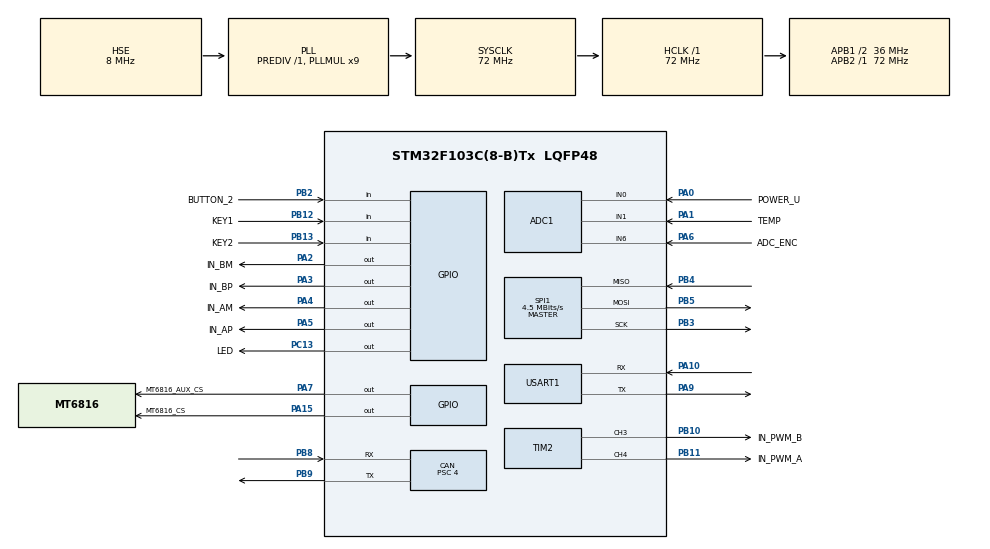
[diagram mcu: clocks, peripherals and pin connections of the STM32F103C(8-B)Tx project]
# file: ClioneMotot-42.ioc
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ADC1.Channel-0\#ChannelRegularConversion=ADC_CHANNEL_0
ADC1.Channel-1\#ChannelRegularConversion=ADC_CHANNEL_1
ADC1.Channel-2\#ChannelRegularConversion=ADC_CHANNEL_6
ADC1.Channel-3\#ChannelRegularConversion=ADC_CHANNEL_TEMPSENSOR
ADC1.NbrOfConversion=4
ADC1.NbrOfConversionFlag=1
ADC1.Rank-0\#ChannelRegularConversion=1
ADC1.Rank-1\#ChannelRegularConversion=2
ADC1.Rank-2\#ChannelRegularConversion=3
ADC1.Rank-3\#ChannelRegularConversion=4
ADC1.SamplingTime-0\#ChannelRegularConversion=ADC_SAMPLETIME_55CYCLES_5
ADC1.SamplingTime-1\#ChannelRegularConversion=ADC_SAMPLETIME_55CYCLES_5
ADC1.SamplingTime-2\#ChannelRegularConversion=ADC_SAMPLETIME_55CYCLES_5
ADC1.SamplingTime-3\#ChannelRegularConversion=ADC_SAMPLETIME_55CYCLES_5
ADC1.master=1
CAN.BS1=CAN_BS1_9TQ
CAN.BS2=CAN_BS2_8TQ
CAN.CalculateBaudRate=500000
CAN.CalculateTimeBit=2000
CAN.CalculateTimeQuantum=111.11111111111111
CAN.NART=ENABLE
CAN.Prescaler=4
Dma.ADC1.0.Direction=DMA_PERIPH_TO_MEMORY
Dma.ADC1.0.Instance=DMA1_Channel1
Dma.ADC1.0.MemDataAlignment=DMA_MDATAALIGN_HALFWORD
Dma.ADC1.0.MemInc=DMA_MINC_ENABLE
Dma.ADC1.0.Mode=DMA_CIRCULAR
Dma.ADC1.0.PeriphDataAlignment=DMA_PDATAALIGN_HALFWORD
Dma.ADC1.0.PeriphInc=DMA_PINC_DISABLE
Dma.ADC1.0.Priority=DMA_PRIORITY_HIGH
Dma.Request0=ADC1
Dma.Request1=USART1_RX
Dma.Request2=USART1_TX
Dma.USART1_RX.1.Direction=DMA_PERIPH_TO_MEMORY
Dma.USART1_RX.1.Instance=DMA1_Channel5
Dma.USART1_RX.1.MemDataAlignment=DMA_MDATAALIGN_BYTE
Dma.USART1_RX.1.MemInc=DMA_MINC_ENABLE
Dma.USART1_RX.1.Mode=DMA_NORMAL
Dma.USART1_RX.1.PeriphDataAlignment=DMA_PDATAALIGN_BYTE
Dma.USART1_RX.1.PeriphInc=DMA_PINC_DISABLE
Dma.USART1_RX.1.Priority=DMA_PRIORITY_HIGH
Dma.USART1_TX.2.Direction=DMA_MEMORY_TO_PERIPH
Dma.USART1_TX.2.Instance=DMA1_Channel4
Dma.USART1_TX.2.MemDataAlignment=DMA_MDATAALIGN_BYTE
Dma.USART1_TX.2.MemInc=DMA_MINC_ENABLE
Dma.USART1_TX.2.Mode=DMA_NORMAL
Dma.USART1_TX.2.PeriphDataAlignment=DMA_PDATAALIGN_BYTE
Dma.USART1_TX.2.PeriphInc=DMA_PINC_DISABLE
Dma.USART1_TX.2.Priority=DMA_PRIORITY_HIGH
FREERTOS.Tasks01=defaultTask,24,128,StartDefaultTask,Default,NULL,Dynamic,NULL,NULL
IWDG.Prescaler=IWDG_PRESCALER_64
Mcu.Family=STM32F1
Mcu.Name=STM32F103C(8-B)Tx
Mcu.Package=LQFP48
NVIC.CAN1_RX1_IRQn=true\:5\:0\:false\:false\:true\:true\:true\:true\:true
NVIC.CAN1_SCE_IRQn=true\:5\:0\:false\:false\:true\:true\:true\:true\:true
NVIC.DMA1_Channel1_IRQn=true\:5\:0\:false\:false\:true\:true\:false\:true\:true
NVIC.DMA1_Channel4_IRQn=true\:5\:0\:false\:false\:true\:true\:false\:true\:true
NVIC.DMA1_Channel5_IRQn=true\:5\:0\:false\:false\:true\:true\:false\:true\:true
NVIC.PriorityGroup=NVIC_PRIORITYGROUP_4
NVIC.TIM4_IRQn=true\:15\:0\:false\:false\:true\:false\:false\:true\:true
NVIC.TimeBase=TIM4_IRQn
NVIC.TimeBaseIP=TIM4
NVIC.USART1_IRQn=true\:5\:0\:false\:false\:true\:true\:true\:true\:true
NVIC.USB_HP_CAN1_TX_IRQn=true\:5\:0\:false\:false\:true\:true\:true\:true\:true
NVIC.USB_LP_CAN1_RX0_IRQn=true\:5\:0\:false\:false\:true\:true\:true\:true\:true
PA0-WKUP.GPIO_Label=POWER_U
PA0-WKUP.Signal=ADCx_IN0
PA1.GPIO_Label=TEMP
PA1.Signal=ADCx_IN1
PA10.Mode=Asynchronous
PA10.Signal=USART1_RX
PA13.Mode=Serial_Wire
PA13.Signal=SYS_JTMS-SWDIO
PA14.Mode=Serial_Wire
PA14.Signal=SYS_JTCK-SWCLK
PA15.GPIO_Label=MT6816_CS
PA15.GPIO_Speed=GPIO_SPEED_FREQ_HIGH
PA15.Signal=GPIO_Output
PA2.GPIO_Label=IN_BM
PA2.GPIO_Speed=GPIO_SPEED_FREQ_HIGH
PA2.PinState=GPIO_PIN_SET
PA2.Signal=GPIO_Output
PA3.GPIO_Label=IN_BP
PA3.GPIO_Speed=GPIO_SPEED_FREQ_HIGH
PA3.PinState=GPIO_PIN_SET
PA3.Signal=GPIO_Output
PA4.GPIO_Label=IN_AM
PA4.GPIO_Speed=GPIO_SPEED_FREQ_HIGH
PA4.PinState=GPIO_PIN_SET
PA4.Signal=GPIO_Output
PA5.GPIO_Label=IN_AP
PA5.GPIO_Speed=GPIO_SPEED_FREQ_HIGH
PA5.PinState=GPIO_PIN_SET
PA5.Signal=GPIO_Output
PA6.GPIO_Label=ADC_ENC
PA6.Signal=ADCx_IN6
PA7.GPIO_Label=MT6816_AUX_CS
PA7.GPIO_Speed=GPIO_SPEED_FREQ_HIGH
PA7.Signal=GPIO_Output
PA9.Mode=Asynchronous
PA9.Signal=USART1_TX
PB10.GPIO_Label=IN_PWM_B
PB10.Signal=S_TIM2_CH3
PB11.GPIO_Label=IN_PWM_A
PB11.Signal=S_TIM2_CH4
PB12.GPIO_Label=KEY1
PB12.GPIO_PuPd=GPIO_PULLUP
PB12.Signal=GPIO_Input
PB13.GPIO_Label=KEY2
PB13.Signal=GPIO_Input
PB2.GPIO_Label=BUTTON_2
PB2.GPIO_PuPd=GPIO_PULLUP
PB2.Signal=GPIO_Input
PB3.Mode=Full_Duplex_Master
PB3.Signal=SPI1_SCK
PB4.Mode=Full_Duplex_Master
PB4.Signal=SPI1_MISO
PB5.Mode=Full_Duplex_Master
PB5.Signal=SPI1_MOSI
PB8.Mode=CAN_Activate
PB8.Signal=CAN_RX
PB9.Mode=CAN_Activate
PB9.Signal=CAN_TX
PC13-TAMPER-RTC.GPIO_Label=LED
PC13-TAMPER-RTC.Signal=GPIO_Output
PD0-OSC_IN.Mode=HSE-External-Oscillator
PD0-OSC_IN.Signal=RCC_OSC_IN
PD1-OSC_OUT.Mode=HSE-External-Oscillator
PD1-OSC_OUT.Signal=RCC_OSC_OUT
ProjectManager.HeapSize=0x200
ProjectManager.StackSize=0x400
ProjectManager.TargetToolchain=CMake
RCC.ADCPresc=RCC_ADCPCLK2_DIV6
RCC.AHBFreq_Value=72000000
RCC.APB1CLKDivider=RCC_HCLK_DIV2
RCC.APB1Freq_Value=36000000
RCC.APB1TimFreq_Value=72000000
RCC.APB2Freq_Value=72000000
RCC.APB2TimFreq_Value=72000000
RCC.HCLKFreq_Value=72000000
RCC.PLLMUL=RCC_PLL_MUL9
RCC.PLLSourceVirtual=RCC_PLLSOURCE_HSE
RCC.SYSCLKFreq_VALUE=72000000
RCC.SYSCLKSource=RCC_SYSCLKSOURCE_PLLCLK
RCC.USBFreq_Value=72000000
SH.ADCx_IN0.0=ADC1_IN0,IN0
SH.ADCx_IN1.0=ADC1_IN1,IN1
SH.ADCx_IN6.0=ADC1_IN6,IN6
SH.S_TIM2_CH3.0=TIM2_CH3,PWM Generation3 CH3
SH.S_TIM2_CH4.0=TIM2_CH4,PWM Generation4 CH4
SPI1.BaudRatePrescaler=SPI_BAUDRATEPRESCALER_16
SPI1.CLKPhase=SPI_PHASE_2EDGE
SPI1.CLKPolarity=SPI_POLARITY_HIGH
SPI1.CalculateBaudRate=4.5 MBits/s
SPI1.Direction=SPI_DIRECTION_2LINES
SPI1.Mode=SPI_MODE_MASTER
SPI1.VirtualType=VM_MASTER
TIM2.Channel-PWM\ Generation3\ CH3=TIM_CHANNEL_3
TIM2.Channel-PWM\ Generation4\ CH4=TIM_CHANNEL_4
USART1.VirtualMode=VM_ASYNC
VP_ADC1_TempSens_Input.Mode=IN-TempSens
VP_FREERTOS_VS_CMSIS_V2.Mode=CMSIS_V2
VP_IWDG_VS_IWDG.Mode=IWDG_Activate
VP_SYS_VS_tim4.Mode=TIM4
board=custom

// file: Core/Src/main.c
/* USER CODE BEGIN Header */
/**
  ******************************************************************************
  * @file           : main.c
  * @brief          : Main program body
  ******************************************************************************
  * @attention
  *
  * Copyright (c) 2025 STMicroelectronics.
  * All rights reserved.
  *
  * This software is licensed under terms that can be found in the LICENSE file
  * in the root directory of this software component.
  * If no LICENSE file comes with this software, it is provided AS-IS.
  *
  ******************************************************************************
  */
/* USER CODE END Header */
#include "main.h"
#include "cmsis_os.h"
#include "adc.h"
#include "can.h"
#include "dma.h"
#include "iwdg.h"
#include "spi.h"
#include "tim.h"
#include "usart.h"
#include "gpio.h"

/* USER CODE BEGIN Includes */
#include "CrashLog.h"
/* USER CODE END Includes */

void SystemClock_Config(void);
void MX_FREERTOS_Init(void);

int main(void)
{

  /* MCU Configuration--------------------------------------------------------*/

  /* Reset of all peripherals, Initializes the Flash interface and the Systick. */
  HAL_Init();

  /* Configure the system clock */
  SystemClock_Config();

  /* Initialize all configured peripherals */
  MX_GPIO_Init();
  MX_DMA_Init();
  MX_ADC1_Init();
  MX_CAN_Init();
  MX_SPI1_Init();
  MX_TIM2_Init();
  MX_USART1_UART_Init();
  MX_IWDG_Init();

  /* Init scheduler */
  osKernelInitialize();

  /* Call init function for freertos objects (in cmsis_os2.c) */
  MX_FREERTOS_Init();

  /* Start scheduler */
  osKernelStart();

  /* We should never get here as control is now taken by the scheduler */

  /* Infinite loop */
  while (1)
  {

  }
}

void SystemClock_Config(void)
{
  RCC_OscInitTypeDef RCC_OscInitStruct = {0};
  RCC_ClkInitTypeDef RCC_ClkInitStruct = {0};
  RCC_PeriphCLKInitTypeDef PeriphClkInit = {0};

  /** Initializes the RCC Oscillators according to the specified parameters
  * in the RCC_OscInitTypeDef structure.
  */
  RCC_OscInitStruct.OscillatorType = RCC_OSCILLATORTYPE_LSI|RCC_OSCILLATORTYPE_HSE;
  RCC_OscInitStruct.HSEState = RCC_HSE_ON;
  RCC_OscInitStruct.HSEPredivValue = RCC_HSE_PREDIV_DIV1;
  RCC_OscInitStruct.HSIState = RCC_HSI_ON;
  RCC_OscInitStruct.LSIState = RCC_LSI_ON;
  RCC_OscInitStruct.PLL.PLLState = RCC_PLL_ON;
  RCC_OscInitStruct.PLL.PLLSource = RCC_PLLSOURCE_HSE;
  RCC_OscInitStruct.PLL.PLLMUL = RCC_PLL_MUL9;
  if (HAL_RCC_OscConfig(&RCC_OscInitStruct) != HAL_OK)
  {
    Error_Handler();
  }

  /** Initializes the CPU, AHB and APB buses clocks
  */
  RCC_ClkInitStruct.ClockType = RCC_CLOCKTYPE_HCLK|RCC_CLOCKTYPE_SYSCLK
                              |RCC_CLOCKTYPE_PCLK1|RCC_CLOCKTYPE_PCLK2;
  RCC_ClkInitStruct.SYSCLKSource = RCC_SYSCLKSOURCE_PLLCLK;
  RCC_ClkInitStruct.AHBCLKDivider = RCC_SYSCLK_DIV1;
  RCC_ClkInitStruct.APB1CLKDivider = RCC_HCLK_DIV2;
  RCC_ClkInitStruct.APB2CLKDivider = RCC_HCLK_DIV1;

  if (HAL_RCC_ClockConfig(&RCC_ClkInitStruct, FLASH_LATENCY_2) != HAL_OK)
  {
    Error_Handler();
  }
  PeriphClkInit.PeriphClockSelection = RCC_PERIPHCLK_ADC;
  PeriphClkInit.AdcClockSelection = RCC_ADCPCLK2_DIV6;
  if (HAL_RCCEx_PeriphCLKConfig(&PeriphClkInit) != HAL_OK)
  {
    Error_Handler();
  }
}

void HAL_TIM_PeriodElapsedCallback(TIM_HandleTypeDef *htim)
{
  if (htim->Instance == TIM4)
  {
    HAL_IncTick();
  }
}

void Error_Handler(void)
{
  /* USER CODE BEGIN Error_Handler_Debug */
  LOG_CRASH_HERE();
  /* User can add his own implementation to report the HAL error return state */
  __disable_irq();
  while (1)
  {
  }
  /* USER CODE END Error_Handler_Debug */
}

#ifdef  USE_FULL_ASSERT
/**
  * @brief  Reports the name of the source file and the source line number
  *         where the assert_param error has occurred.
  * @param  file: pointer to the source file name
  * @param  line: assert_param error line source number
  * @retval None
  */
void assert_failed(uint8_t *file, uint32_t line)
{
  /* USER CODE BEGIN 6 */
  LOG_CRASH_HERE();
  /* User can add his own implementation to report the file name and line number,
     ex: printf("Wrong parameters value: file %s on line %d\r\n", file, line) */
  /* USER CODE END 6 */
}
#endif /* USE_FULL_ASSERT */
